# S32K142 register map
Vendor: NXP; Series: S32K; File version: 1.6
CPU: CM4 r0p1, little endian, MPU, FPU, 4 interrupt priority bits
Registers are 32-bit, read-write, reset 0x0 unless marked. A register's access mark holds for its fields unless they carry their own. Offsets are from the block's base; [hi:lo] are bit positions; {n}, {i} and the like mark numbered series.

## CSE_PRAM
Base 0x14001000; register names take the prefix CSE_PRAM
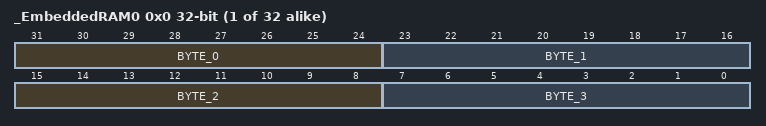
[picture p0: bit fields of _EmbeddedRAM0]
{0x0+4i} _EmbeddedRAM{i} (CSE_PRAM view) (i=0..31) — CSE PRAM {i} Register
  [31-8n:24-8n] BYTE_{n} (n=0..3) — Data byte {n} of Rx/Tx frame.
{0x0+4i} _EmbeddedRAM{i}LL 8-bit (CSE_PRAM view) (i=0..31) — CSE PRAM{i}LL register.
  [7:0] RAM_LL — RAM_LL stores the first 8 bits of the 32 bit CRC
{0x1+4i} _EmbeddedRAM{i}LU 8-bit (i=0..31) — CSE PRAM{i}LU register.
  [7:0] RAM_LU — RAM_LU stores the second 8 bits of the 32 bit CRC
{0x2+4i} _EmbeddedRAM{i}HL 8-bit (i=0..31) — CSE PRAM{i}HL register.
  [7:0] RAM_HL — RAM_HL stores the third 8 bits of the 32 bit CRC
{0x3+4i} _EmbeddedRAM{i}HU 8-bit (i=0..31) — CSE PRAM{i}HU register.
  [7:0] RAM_HU — RAM_HU stores the fourth 8 bits of the 32 bit CRC

## ERM
Base 0x40018000; register names take the prefix ERM_
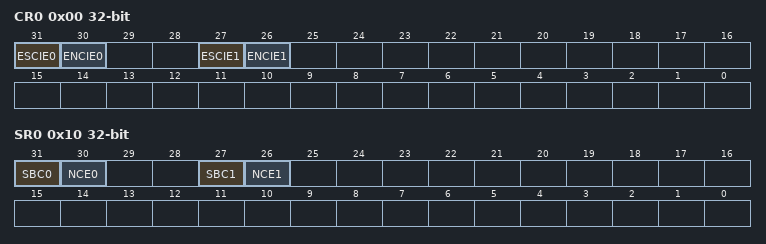
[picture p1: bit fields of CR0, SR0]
0x00 CR0 — ERM Configuration Register 0
  [31] ESCIE0
    0=Interrupt notification of Memory 0 single-bit correction events is disabled; 1=Interrupt notification of Memory 0 single-bit correction events is enabled
  [30] ENCIE0
    0=Interrupt notification of Memory 0 non-correctable error events is disabled; 1=Interrupt notification of Memory 0 non-correctable error events is enabled
  [27] ESCIE1
    0=Interrupt notification of Memory 1 single-bit correction events is disabled; 1=Interrupt notification of Memory 1 single-bit correction events is enabled
  [26] ENCIE1
    0=Interrupt notification of Memory 1 non-correctable error events is disabled; 1=Interrupt notification of Memory 1 non-correctable error events is enabled
0x10 SR0 — ERM Status Register 0
  [31] SBC0
    0=No single-bit correction event on Memory 0 detected; 1=Single-bit correction event on Memory 0 detected
  [30] NCE0
    0=No non-correctable error event on Memory 0 detected; 1=Non-correctable error event on Memory 0 detected
  [27] SBC1
    0=No single-bit correction event on Memory 1 detected; 1=Single-bit correction event on Memory 1 detected
  [26] NCE1
    0=No non-correctable error event on Memory 1 detected; 1=Non-correctable error event on Memory 1 detected
0x100 EAR0 ro — ERM Memory n Error Address Register
  [31:0] EAR
0x110 EAR1 ro — ERM Memory n Error Address Register
  [31:0] EAR

## EIM — Error Injection Module
Base 0x40019000; register names take the prefix EIM_
0x00 EIMCR — Error Injection Module Configuration Register
  [0] GEIEN — Global Error Injection Enable
    0=Disabled; 1=Enabled
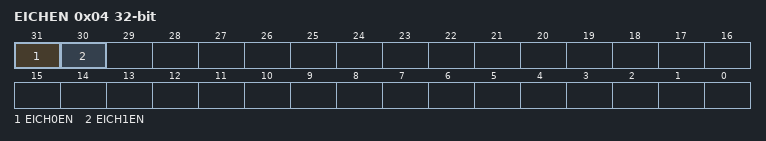
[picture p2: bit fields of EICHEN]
0x04 EICHEN — Error Injection Channel Enable register
  [31] EICH0EN — Error Injection Channel 0 Enable
    0=Error injection is disabled on Error Injection Channel 0; 1=Error injection is enabled on Error Injection Channel 0
  [30] EICH1EN — Error Injection Channel 1 Enable
    0=Error injection is disabled on Error Injection Channel 1; 1=Error injection is enabled on Error Injection Channel 1
0x100 EICHD0_WORD0 — Error Injection Channel Descriptor n, Word0
  [31:25] CHKBIT_MASK — Checkbit Mask
0x104 EICHD0_WORD1 — Error Injection Channel Descriptor n, Word1
  [31:0] B0_3DATA_MASK — Data Mask Bytes 0-3
0x200 EICHD1_WORD0 — Error Injection Channel Descriptor n, Word0
  [31:25] CHKBIT_MASK — Checkbit Mask
0x204 EICHD1_WORD1 — Error Injection Channel Descriptor n, Word1
  [31:0] B0_3DATA_MASK — Data Mask Bytes 0-3

## DMAMUX — DMA channel multiplexor
Base 0x40021000; register names take the prefix DMAMUX_
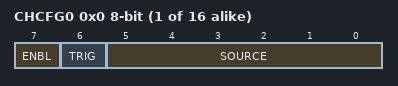
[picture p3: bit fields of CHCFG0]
{0x0+i} CHCFG{i} 8-bit (i=0..15) — Channel Configuration register
  [7] ENBL — DMA Channel Enable
    0=DMA channel is disabled. This mode is primarily used during configuration of the DMAMux. The DMA has separate channel enables/disables, which should be used to disable or reconfigure a DMA channel.; 1=DMA channel is enabled
  [6] TRIG — DMA Channel Trigger Enable
    0=Triggering is disabled. If triggering is disabled and ENBL is set, the DMA Channel will simply route the specified source to the DMA channel. (Normal mode); 1=Triggering is enabled. If triggering is enabled and ENBL is set, the DMAMUX is in Periodic Trigger mode.
  [5:0] SOURCE — DMA Channel Source (Slot)

## Notices in the file
Redistribution and use in source and binary forms, with or without modification,
are permitted provided that the following conditions are met:
o Redistributions of source code must retain the above copyright notice, this list
of conditions and the following disclaimer.
o Redistributions in binary form must reproduce the above copyright notice, this
list of conditions and the following disclaimer in the documentation and/or
other materials provided with the distribution.
o Neither the name of Freescale Semiconductor, Inc. nor the names of its
contributors may be used to endorse or promote products derived from this
software without specific prior written permission.
THIS SOFTWARE IS PROVIDED BY THE COPYRIGHT HOLDERS AND CONTRIBUTORS "AS IS" AND
ANY EXPRESS OR IMPLIED WARRANTIES, INCLUDING, BUT NOT LIMITED TO, THE IMPLIED
WARRANTIES OF MERCHANTABILITY AND FITNESS FOR A PARTICULAR PURPOSE ARE
DISCLAIMED. IN NO EVENT SHALL THE COPYRIGHT HOLDER OR CONTRIBUTORS BE LIABLE FOR
ANY DIRECT, INDIRECT, INCIDENTAL, SPECIAL, EXEMPLARY, OR CONSEQUENTIAL DAMAGES
(INCLUDING, BUT NOT LIMITED TO, PROCUREMENT OF SUBSTITUTE GOODS OR SERVICES;
LOSS OF USE, DATA, OR PROFITS; OR BUSINESS INTERRUPTION) HOWEVER CAUSED AND ON
ANY THEORY OF LIABILITY, WHETHER IN CONTRACT, STRICT LIABILITY, OR TORT
(INCLUDING NEGLIGENCE OR OTHERWISE) ARISING IN ANY WAY OUT OF THE USE OF THIS
SOFTWARE, EVEN IF ADVISED OF THE POSSIBILITY OF SUCH DAMAGE.
